VERSION ""

NS_ :

BS_:

BU_: VCU OBC
VAL_TABLE_ HOLD_DISCONTACTOR_WUP_STATE 1 "Wakeup on going" 0 "No wakeup in progress" ;

BO_ 3221225472 VECTOR__INDEPENDENT_SIG_MSG: 0 Vector__XXX
 SG_ VCU_RollingCounter372 : 0|4@0+ (1,0) [0|15] "" Vector__XXX
 SG_ VCU_FrameChksum372 : 0|4@0+ (1,0) [0|15] "" Vector__XXX

BO_ 197 DCDC_DC2: 8 OBC
 SG_ DCDC_OutputCurrent : 47|12@0+ (0.1,0) [0|254] "A"  VCU
 SG_ DCDC_InputCurrent : 39|8@0+ (0.1,0) [0|25.4] "A"  VCU

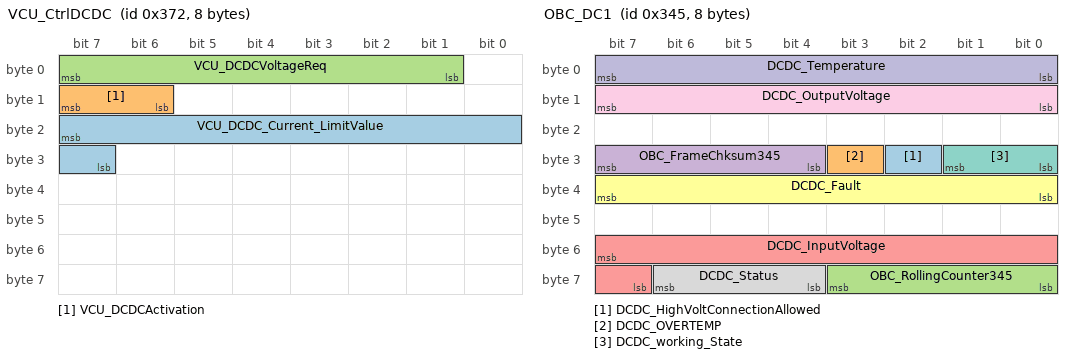
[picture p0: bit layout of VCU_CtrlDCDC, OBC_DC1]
BO_ 882 VCU_CtrlDCDC: 8 VCU
 SG_ VCU_DCDC_Current_LimitValue : 23|9@0+ (1,0) [0|511] "A" Vector__XXX
 SG_ VCU_DCDCActivation : 15|2@0+ (1,0) [0|3] ""  OBC
 SG_ VCU_DCDCVoltageReq : 7|7@0+ (0.05,10.6) [10.6|16] "V"  OBC

BO_ 837 OBC_DC1: 8 OBC
 SG_ DCDC_HighVoltConnectionAllowed : 26|1@0+ (1,0) [0|1] ""  VCU
 SG_ DCDC_OVERTEMP : 27|1@0+ (1,0) [0|0] "" Vector__XXX
 SG_ OBC_RollingCounter345 : 59|4@0+ (1,0) [0|15] ""  VCU
 SG_ OBC_FrameChksum345 : 31|4@0+ (1,0) [0|15] ""  VCU
 SG_ DCDC_InputVoltage : 55|9@0+ (1,0) [0|500] "V"  VCU
 SG_ DCDC_Fault : 39|8@0+ (1,0) [0|255] ""  VCU
 SG_ DCDC_working_State : 25|2@0+ (1,0) [0|3] ""  VCU
 SG_ DCDC_Status : 62|3@0+ (1,0) [0|7] ""  VCU
 SG_ DCDC_OutputVoltage : 15|8@0+ (0.1,4) [4|21.5] "V"  VCU
 SG_ DCDC_Temperature : 7|8@0+ (1,-40) [-40|214] "Degree Celsius"  VCU

CM_ "$File: //depot/auto/dbc/Third_party_components/META_DCDC/META_DCDC_MSCXX1003/0.0.5.0/META_DCDC_MSCXX1003.dbc $
$Change: 215988 $
$DateTime: 2024/08/21 10:13:57 $
$Revision: #1 $";
CM_ BO_ 3221225472 "This is a message for not used signals, created by Vector CANdb++ DBC OLE DB Provider.";
CM_ SG_ 197 DCDC_InputCurrent "Invalid Value 0xFF";
CM_ SG_ 882 VCU_DCDCActivation "Invalid value 0x03";
CM_ SG_ 882 VCU_DCDCVoltageReq "InvaildValue0x7F";
CM_ SG_ 837 DCDC_InputVoltage "default value 0x00,
Invalid value 0x1FF";
CM_ SG_ 837 DCDC_Fault "bit6-7:Indicates the severity of the problem
0x00 Abnormal warning  
0x01 Serious fault  
0x02 Temporary fatal  
0x03 Permanent damage 
bit0-5: Indicates the type of fault";
BA_DEF_ SG_  "GenSigStartValue" FLOAT 0 100000000000;
BA_DEF_ SG_  "GenSigSendType" ENUM  "Cyclic","OnWrite","OnWriteWithRepetition","OnChange","OnChangeWithRepetition","IfActive","IfActiveWithRepetition","NoSigSendType","NotUsed","NotUsed","NotUsed","NotUsed","NotUsed";
BA_DEF_ BO_  "GenMsgSendType" ENUM  "Cyclic","Event","Event&Cyclic","NotUsed","NotUsed","NotUsed","NotUsed","IfActive","NoMsgSendType","NotUsed","vector_leerstring";
BA_DEF_ BO_  "GenMsgCycleTime" INT 0 50000;
BA_DEF_ BO_  "GenMsgCycleTimeFast" INT 0 50000;
BA_DEF_ BO_  "GenMsgILSupport" ENUM  "No","Yes";
BA_DEF_ BU_  "NodeLayerModules" STRING ;
BA_DEF_  "NmBaseAddress" HEX 1024 1087;
BA_DEF_ BO_  "Producer" STRING ;
BA_DEF_DEF_  "GenSigStartValue" 0;
BA_DEF_DEF_  "GenSigSendType" "Cyclic";
BA_DEF_DEF_  "GenMsgSendType" "NoMsgSendType";
BA_DEF_DEF_  "GenMsgCycleTime" 0;
BA_DEF_DEF_  "GenMsgCycleTimeFast" 0;
BA_DEF_DEF_  "GenMsgILSupport" "Yes";
BA_DEF_DEF_  "NodeLayerModules" "CANoeILNLVector.dll";
BA_DEF_DEF_  "NmBaseAddress" 1024;
BA_ "GenMsgSendType" BO_ 197 0;
BA_ "GenMsgCycleTime" BO_ 197 100;
BA_ "GenMsgCycleTimeFast" BO_ 197 100;
BA_ "GenMsgCycleTimeFast" BO_ 882 100;
BA_ "GenMsgCycleTime" BO_ 882 100;
BA_ "GenMsgSendType" BO_ 882 0;
BA_ "GenMsgCycleTimeFast" BO_ 837 100;
BA_ "GenMsgCycleTime" BO_ 837 100;
BA_ "GenMsgSendType" BO_ 837 0;
BA_ "GenSigStartValue" SG_ 3221225472 VCU_FrameChksum372 12;
BA_ "GenSigStartValue" SG_ 882 VCU_DCDCActivation 1;
BA_ "GenSigStartValue" SG_ 837 DCDC_Temperature 40;
BA_ "Producer" BO_ 882 "LVPS";
VAL_ 882 VCU_DCDCActivation 3 "Unavaliable Value" 2 "DCDC ON" 1 "DCDC OFF" 0 "Not used" ;
VAL_ 837 DCDC_HighVoltConnectionAllowed 1 "Permit" 0 "Not Permit" ;
VAL_ 837 DCDC_OVERTEMP 1 "OverTempature" 0 "False" ;
VAL_ 837 DCDC_Fault 137 "Shortcircuit_Protection" 136 "Output_Overcurrent" 135 "Output_Overvoltage" 134 "Cavity_Overcurrent" 133 "Temp_Sensor_Faullt" 132 "CoolantTemp_tooHigh" 131 "CoolantTemp_tooLow" 130 "BatVolt12V_tooLow" 129 "BatVolt12V_tooHigh" 71 "ROM_Timeout" 70 "RAM_Timeout" 69 "Send_Message_Timeout" 68 "VCU_Node_Loss" 67 "BMS_Node_Loss" 66 "CGW_Node_Loss" 65 "Bus_Off" 192 "InVoltage_OverVoltage" 128 "InVoltage_UnderVoltage" 64 "Abnormal_WakeUp" 0 "No_Fault" ;
VAL_ 837 DCDC_working_State 3 "reserved" 2 "DCDC is standby" 1 "reserved" 0 "DCDC converting" ;
VAL_ 837 DCDC_Status 7 "invalid" 6 "reserved" 5 "degradation mode" 4 "error mode" 3 "conversion working" 2 "standby mode" 1 "Init mode" 0 "off mode" ;
